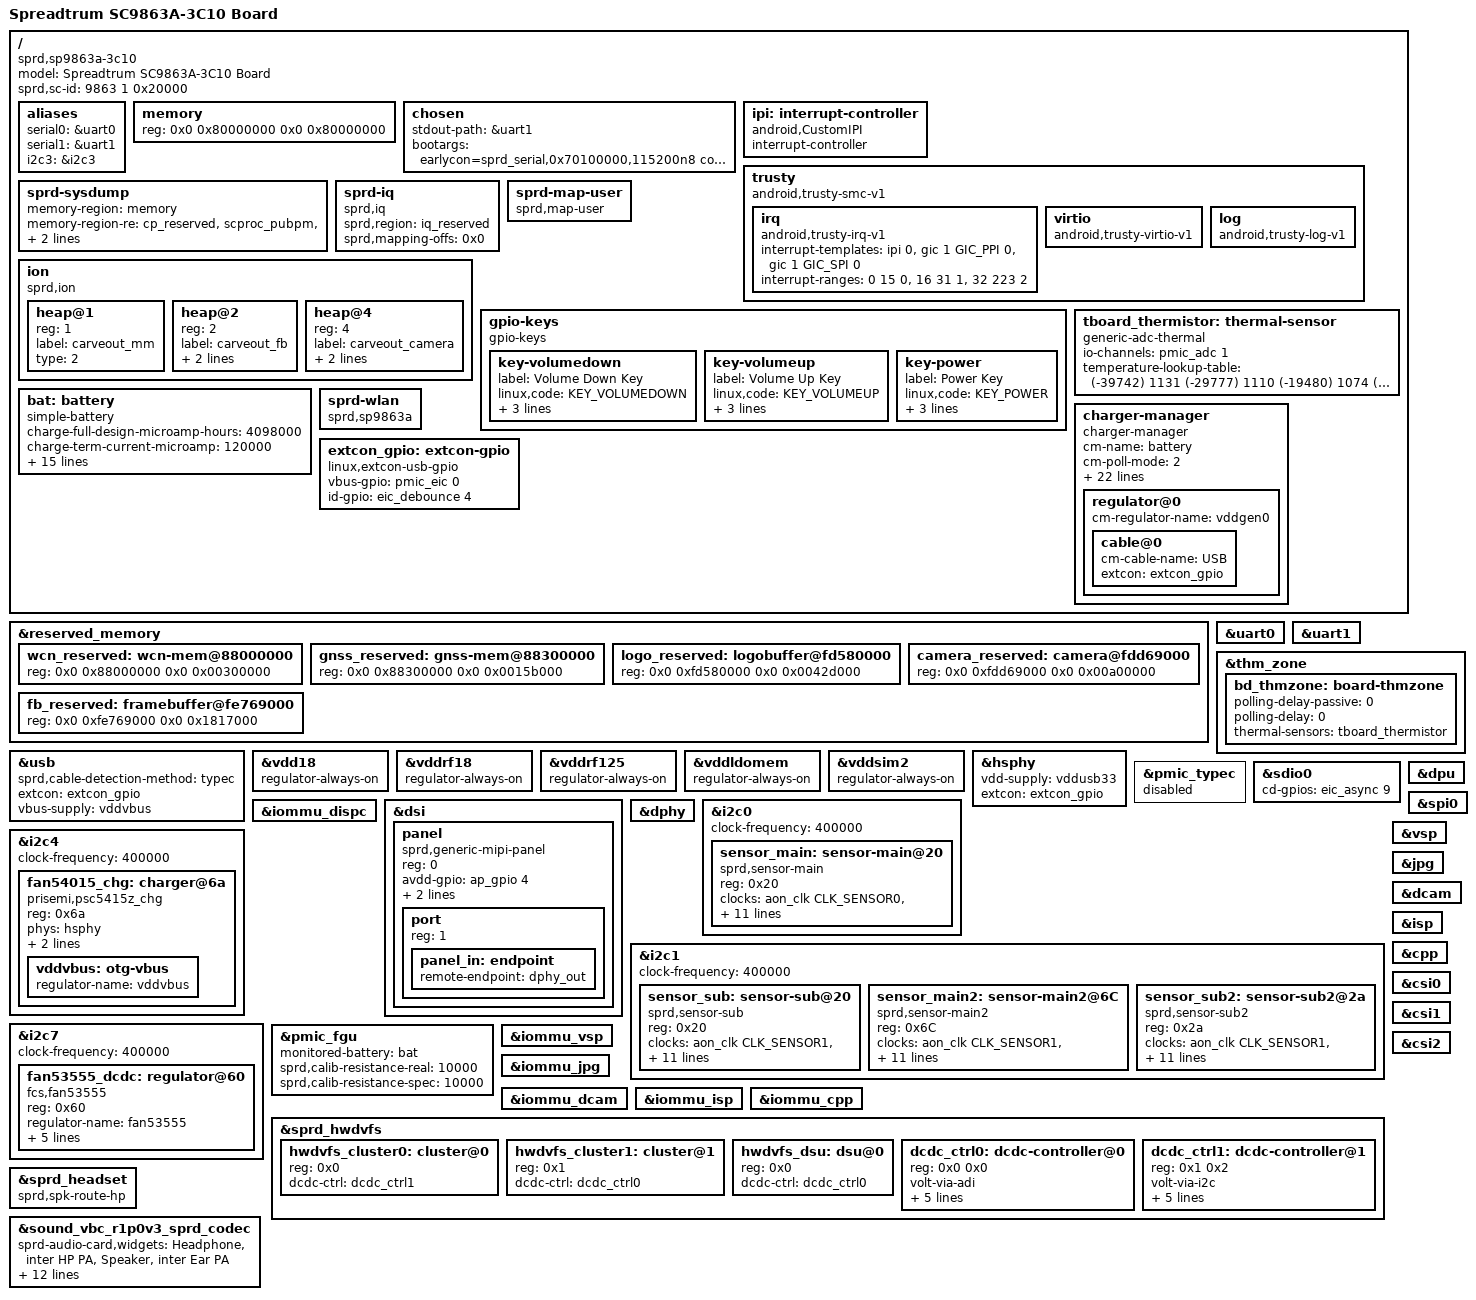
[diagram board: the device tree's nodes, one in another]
// SPDX-License-Identifier: (GPL-2.0+ OR MIT)
/*
 * Spreadtrum Sharkl3 platform DTS file
 *
 * Copyright (C) 2018, Spreadtrum Communications Inc.
 */

/dts-v1/;

#include "sc9863a.dtsi"
#include "sc9863a-wcn.dtsi"
#include "sp9863a-mach.dtsi"
#include "lcd/lcd_jd9365z_king_mipi_hdp.dtsi"
#include <dt-bindings/gpio/gpio.h>
#include <dt-bindings/input/input.h>

/ {
	model = "Spreadtrum SC9863A-3C10 Board";

	compatible = "sprd,sp9863a-3c10", "sprd,sc9863a";

	sprd,sc-id = <9863 1 0x20000>;

	aliases {
		serial0 = &uart0;
		serial1 = &uart1;
		i2c3 = &i2c3;
	};

	memory: memory {
		device_type = "memory";
		reg = <0x0 0x80000000 0x0 0x80000000>;
	};

	chosen {
		stdout-path = &uart1;
		bootargs = "earlycon=sprd_serial,0x70100000,115200n8 console=ttyS1,115200n8 loglevel=1 init=/init root=/dev/ram0 rw androidboot.hardware=s9863a3c10 androidboot.dtbo_idx=0 printk.devkmsg=on androidboot.boot_devices=soc/soc:ap-ahb/20600000.sdio";
	};

	ipi: interrupt-controller {
		compatible = "android,CustomIPI";
		#interrupt-cells = <1>;
		interrupt-controller;
	};

	trusty {
		compatible = "android,trusty-smc-v1";

		irq {
			compatible = "android,trusty-irq-v1";
			interrupt-templates = <&ipi 0>,
						<&gic 1 GIC_PPI 0>,
						<&gic 1 GIC_SPI 0>;
			interrupt-ranges = < 0  15 0>,
						<16  31 1>,
						<32 223 2>;
		};

		virtio {
			compatible = "android,trusty-virtio-v1";
		};

		log {
			compatible = "android,trusty-log-v1";
		};
	};

	sprd-sysdump {
		memory-region = <&memory>;
		memory-region-re = <&cp_reserved>, <&scproc_pubpm>, <&smem_reserved>,
				<&gnss_reserved>, <&wcn_reserved>;
		memory-region-se = <&tos_reserved>, <&sml_reserved>;
	};

	sprd-iq {
		compatible = "sprd,iq";
		sprd,region = <&iq_reserved>;
		sprd,mapping-offs = <0x0>;
	};

	sprd-map-user {
		compatible = "sprd,map-user";
	};

	ion {
		compatible = "sprd,ion";
		#address-cells = <1>;
		#size-cells = <0>;

		heap@1 {
			reg = <1>;
			label = "carveout_mm";
			type = <2>;
		};

		heap@2 {
			reg = <2>;
			label = "carveout_fb";
			type = <2>;
			memory-region = <&fb_reserved>;
		};

		heap@4 {
			reg = <4>;
			label = "carveout_camera";
			type = <2>;
			memory-region = <&camera_reserved>;
		};
	};

	gpio-keys {
		compatible = "gpio-keys";

		key-volumedown {
			label = "Volume Down Key";
			linux,code = <KEY_VOLUMEDOWN>;
			gpios = <&pmic_eic 10 GPIO_ACTIVE_HIGH>;
			debounce-interval = <2>;
			wakeup-source;
		};

		key-volumeup {
			label = "Volume Up Key";
			linux,code = <KEY_VOLUMEUP>;
			gpios = <&ap_gpio 124 GPIO_ACTIVE_LOW>;
			debounce-interval = <2>;
			wakeup-source;
		};

		key-power {
			label = "Power Key";
			linux,code = <KEY_POWER>;
			gpios = <&pmic_eic 1 GPIO_ACTIVE_LOW>;
			debounce-interval = <2>;
			wakeup-source;
		};
	};

	tboard_thermistor:thermal-sensor {
		compatible = "generic-adc-thermal";
		#thermal-sensor-cells = <0>;
		io-channels = <&pmic_adc 1>;
		io-channel-names = "sensor-channel";
		temperature-lookup-table = <	(-39742) 1131
						(-29777) 1110
						(-19480) 1074
						(-4679) 983
						10110 838
						24805 654
						44922 413
						54903 316
						64895 238
						74884 178
						84883 133
						94883 100
						104880 75
						114889 57
						124872 43 >;
	};

	bat: battery {
		compatible = "simple-battery";
		charge-full-design-microamp-hours = <4098000>;
		charge-term-current-microamp = <120000>;
		constant_charge_voltage_max_microvolt = <4400000>;
		factory-internal-resistance-micro-ohms = <286000>;
		voltage-min-design-microvolt = <3450000>;
		ocv-capacity-celsius = <20>;
		ocv-capacity-table-0 = <4377000 100>, <4307000 95>, <4246000 90>,
					<4187000 85>, <4131000 80>, <4078000 75>,
					<4029000 70>, <3979000 65>, <3939000 60>,
					<3887000 55>, <3850000 50>, <3824000 45>,
					<3803000 40>, <3787000 35>, <3775000 30>,
					<3763000 25>, <3744000 20>, <3718000 15>,
					<3688000 10>, <3671000 5>, <3400000 0>;
		charge-sdp-current-microamp = <500000 500000>;
		charge-dcp-current-microamp = <1150000 3000000>;
		charge-cdp-current-microamp = <1150000 1150000>;
		charge-unknown-current-microamp = <500000 500000>;
	};

	charger-manager {
		compatible = "charger-manager";
		cm-name = "battery";
		cm-poll-mode = <2>;
		cm-poll-interval = <15000>;
		cm-battery-stat = <2>;

		cm-fullbatt-vchkdrop-ms = <30000>;
		cm-fullbatt-vchkdrop-volt = <60000>;
		cm-fullbatt-voltage = <4300000>;
		cm-fullbatt-current = <120000>;
		cm-fullbatt-capacity = <100>;

		cm-num-chargers = <1>;
		cm-chargers = "fan54015_charger";
		cm-fuel-gauge = "sc27xx-fgu";

		/* in deci centigrade */
		cm-battery-cold = <200>;
		cm-battery-cold-in-minus;
		cm-battery-hot = <800>;
		cm-battery-temp-diff = <100>;

		/* Allow charging for 6hr */
		cm-charging-max = <21600000>;
		/* recovery charging after stop charging 45min */
		cm-discharging-max = <2700000>;

		/* the interval to feed charger watchdog */
		cm-wdt-interval = <60>;

		/* drop voltage in microVolts to allow shutdown */
		cm-shutdown-voltage = <3100000>;

		/* when 99% of the time is exceeded, it will be forced to 100% */
		cm-tickle-time-out = <1500>;

		/* how much time to allow capacity change */
		cm-one-cap-time = <30>;

		/* when the safe charging voltage is exceeded, stop charging */
		cm-charge-voltage-max = <6500000>;
		/* drop voltage in microVolts to restart charging */
		cm-charge-voltage-drop = <700000>;

		regulator@0 {
			cm-regulator-name = "vddgen0";
			cable@0 {
				cm-cable-name = "USB";
				extcon = <&extcon_gpio>;
			};
		};
	};

	sprd-wlan {
		compatible = "sprd,sp9863a";
	};

	extcon_gpio: extcon-gpio {
		compatible = "linux,extcon-usb-gpio";
		vbus-gpio = <&pmic_eic 0 GPIO_ACTIVE_HIGH>;
		id-gpio = <&eic_debounce 4 GPIO_ACTIVE_HIGH>;
	};
};

&reserved_memory {

	wcn_reserved: wcn-mem@88000000 {
		reg = <0x0 0x88000000 0x0 0x00300000>;
	};

	gnss_reserved: gnss-mem@88300000 {
		reg = <0x0 0x88300000 0x0 0x0015b000>;
	};

	logo_reserved: logobuffer@fd580000{
		reg = <0x0 0xfd580000 0x0 0x0042d000>;
	};

	camera_reserved: camera@fdd69000{
		reg = <0x0 0xfdd69000 0x0 0x00a00000>;
	};

	fb_reserved: framebuffer@fe769000 {
		reg = <0x0 0xfe769000 0x0 0x1817000>;
	};
};

&uart0 {
	status = "okay";
};

&uart1 {
	status = "okay";
};

&thm_zone {
	bd_thmzone: board-thmzone {
		polling-delay-passive = <0>;
		polling-delay = <0>;
		thermal-sensors = <&tboard_thermistor>;
	};
};

&usb {
	sprd,cable-detection-method = "typec";
};

&vdd18 {
	regulator-always-on;
};

&vddrf18 {
	regulator-always-on;
};

&vddrf125 {
	regulator-always-on;
};

&vddldomem {
	regulator-always-on;
};

&vddsim2 {
	regulator-always-on;
};

&hsphy {
	vdd-supply = <&vddusb33>;
	extcon = <&extcon_gpio>;
};

&usb {
	extcon = <&extcon_gpio>;
	vbus-supply = <&vddvbus>;
};

&pmic_typec {
	status = "disable";
};

&sdio0 {
	cd-gpios = <&eic_async 9 0>;
};

&dpu {
	status = "okay";
};

&iommu_dispc {
	status = "okay";
};

&dsi {
	status = "okay";
	#address-cells = <1>;
	#size-cells = <0>;

	panel: panel {
		compatible = "sprd,generic-mipi-panel";
		#address-cells = <1>;
		#size-cells = <0>;
		reg = <0>;

		avdd-gpio = <&ap_gpio 4 GPIO_ACTIVE_HIGH>;
		avee-gpio = <&ap_gpio 5 GPIO_ACTIVE_HIGH>;
		reset-gpio = <&ap_gpio 50 GPIO_ACTIVE_HIGH>;
		port {
			reg = <1>;
			panel_in: endpoint {
				remote-endpoint = <&dphy_out>;
			};
		};
	};
};

&dphy {
	status = "okay";
};

&i2c0 {
	status = "okay";
	clock-frequency = <400000>;

	sensor_main: sensor-main@20 {
		compatible = "sprd,sensor-main";
		reg = <0x20>;
		clock-names = "clk_src","sensor_eb",
			"clk_96m","clk_76m8",
			"clk_48m","clk_26m";
		clocks = <&aon_clk CLK_SENSOR0>, <&mm_gate CLK_SENSOR0_EB>,
			<&pll CLK_TWPLL_96M>,<&pll CLK_TWPLL_76M8>,
			<&pll CLK_TWPLL_48M>,<&ext_26m>;
		avdd-gpios = <&ap_gpio 85 0>;
		dvdd-gpios = <&ap_gpio 11 0>;
		iovdd-gpios = <&ap_gpio 28 0>;
		vddcammot-supply = <&vddcammot>;
		sprd,phyid = <1>;
		csi = <&csi0>;
		reset-gpios = <&ap_gpio 44 0>;
		power-down-gpios = <&ap_gpio 46 0>;
	};
};

&i2c1 {
	status = "okay";
	clock-frequency = <400000>;

	sensor_sub: sensor-sub@20 {
		compatible = "sprd,sensor-sub";
		reg = <0x20>;
		clock-names = "clk_src","sensor_eb",
			"clk_96m","clk_76m8",
			"clk_48m","clk_26m";
		clocks = <&aon_clk CLK_SENSOR1>, <&mm_gate CLK_SENSOR1_EB>,
			<&pll CLK_TWPLL_96M>,<&pll CLK_TWPLL_76M8>,
			<&pll CLK_TWPLL_48M>,<&ext_26m>;
		avdd-gpios = <&ap_gpio 85 0>;
		dvdd-gpios = <&ap_gpio 87 0>;
		iovdd-gpios = <&ap_gpio 28 0>;
		vddcammot-supply = <&vddcammot>;
		sprd,phyid = <0>;
		csi = <&csi0>;
		reset-gpios = <&ap_gpio 41 0>;
		power-down-gpios = <&ap_gpio 40 0>;
	};

	sensor_main2: sensor-main2@6C {
		compatible = "sprd,sensor-main2";
		reg = <0x6C>;
		clock-names = "clk_src","sensor_eb",
			"clk_96m","clk_76m8",
			"clk_48m","clk_26m";
		clocks = <&aon_clk CLK_SENSOR1>, <&mm_gate CLK_SENSOR1_EB>,
			<&pll CLK_TWPLL_96M>,<&pll CLK_TWPLL_76M8>,
			<&pll CLK_TWPLL_48M>,<&ext_26m>;
		dvdd-gpios = <&ap_gpio 29 0>;
		vddio-supply = <&vddcamio>;
		vddcama-supply = <&vddcama>;
		vddcammot-supply = <&vddcammot>;
		sprd,phyid = <2>;
		csi = <&csi1>;
		reset-gpios = <&ap_gpio 45 0>;
		power-down-gpios = <&ap_gpio 47 0>;
	};

	sensor_sub2: sensor-sub2@2a {
		compatible = "sprd,sensor-sub2";
		reg = <0x2a>;
		clock-names = "clk_src","sensor_eb",
			"clk_96m","clk_76m8",
			"clk_48m","clk_26m";
		clocks = <&aon_clk CLK_SENSOR1>, <&mm_gate CLK_SENSOR1_EB>,
			<&pll CLK_TWPLL_96M>,<&pll CLK_TWPLL_76M8>,
			<&pll CLK_TWPLL_48M>,<&ext_26m>;
		vddio-supply = <&vddcamio>;
		vddcama-supply = <&vddcama>;
		vddcamd-supply = <&vddcamd>;
		vddcammot-supply = <&vddcammot>;
		sprd,phyid = <4>;
		csi = <&csi2>;
		/*avdd-gpios=<&ap_gpio 140 0>;*/
		reset-gpios = <&ap_gpio 45 0>;
		power-down-gpios = <&ap_gpio 40 0>;
	};
};

&i2c4 {
	status = "okay";
	clock-frequency = <400000>;

	fan54015_chg: charger@6a {
		compatible = "prisemi,psc5415z_chg";
		reg = <0x6a>;
		phys = <&hsphy>;
		monitored-battery = <&bat>;
		extcon = <&extcon_gpio>;
		vddvbus:otg-vbus {
			regulator-name = "vddvbus";
		};
	};
};

&spi0 {
	/*used for fingerprint sensor*/
	status = "okay";
};

&i2c7 {
	status = "okay";
	clock-frequency = <400000>;

	fan53555_dcdc: regulator@60 {
		compatible = "fcs,fan53555";
		reg = <0x60>;
		regulator-name = "fan53555";
		regulator-min-microvolt = <603000>;
		regulator-max-microvolt = <1411000>;
		regulator-ramp-delay = <64000>;
		regulator-always-on;
		fcs,suspend-voltage-selector = <1>;
	};
};

&vsp {
	status = "okay";
};

&pmic_fgu {
	monitored-battery = <&bat>;
	sprd,calib-resistance-real = <10000>;
	sprd,calib-resistance-spec = <10000>;
};

&jpg {
	status = "okay";
};

&iommu_vsp {
	status = "okay";
};

&iommu_jpg {
	status = "okay";
};

&dcam {
	status = "okay";
};

&iommu_dcam {
	status = "okay";
};

&isp {
	status = "okay";
};

&iommu_isp {
	status = "okay";
};

&cpp {
	status = "okay";
};

&iommu_cpp {
	status = "okay";
};

&csi0 {
	status = "okay";
};

&csi1 {
	status = "okay";
};

&csi2 {
	status = "okay";
};

&sprd_hwdvfs {
	hwdvfs_cluster0: cluster@0 {
		reg = <0x0>;
		dcdc-ctrl = <&dcdc_ctrl1>;
	};

	hwdvfs_cluster1: cluster@1 {
		reg = <0x1>;
		dcdc-ctrl = <&dcdc_ctrl0>;
	};

	hwdvfs_dsu: dsu@0 {
		reg = <0x0>;
		dcdc-ctrl = <&dcdc_ctrl0>;
	};

	dcdc_ctrl0: dcdc-controller@0 {
		reg = <0x0 0x0>;
		volt-via-adi;
		volt-hold-us = <50>;
		volt-pause-us = <5>;
		volt-timeout-us = <800>;
		volt-stable-us  = <5>;
		volt-max-step-microvolt = <25000>;
	};

	dcdc_ctrl1: dcdc-controller@1 {
		reg = <0x1 0x2>;
		volt-via-i2c;
		volt-hold-us = <25>;
		volt-pause-us = <20>;
		volt-timeout-us = <800>;
		volt-stable-us  = <25>;
		volt-max-step-microvolt = <1200004>;
	};
};

&sprd_headset {
	sprd,spk-route-hp;
};

&sound_vbc_r1p0v3_sprd_codec {
	status = "okay";
	sprd-audio-card,widgets =
		"Headphone", "inter HP PA",
		"Speaker", "inter Ear PA";
	sprd-audio-card,routing =
		"HPMIC", "HP Mic Jack",
		"MIC", "Mic Jack",
		"AUXMIC", "Aux Mic Jack",
		"inter HP PA", "HP PA",
		"Ext Spk", "HP PA",
		"inter Ear PA", "EAR",
		"DMIC", "DMic Jack",
		"DMIC1", "DMic1 Jack",

		/* For vbc loopback */
		"Aud input", "AD Clk",
		"Aud input1", "AD Clk",
		"Aud input", "Digital ADCL Switch",
		"Aud input", "Digital ADCR Switch",
		"Aud input1", "Digital ADC1L Switch",
		"Aud input1", "Digital ADC1R Switch";


	/*ext_control_type, hook selection, mode, gpio share*/
	sprd,spk-ext-pa-info = <0 0 4 0>;

	sprd,spk-ext-pa-gpio = <&ap_gpio 33 GPIO_ACTIVE_HIGH>;

	sprd,spk-ext-pa-names = "ext_spk_r";
};
